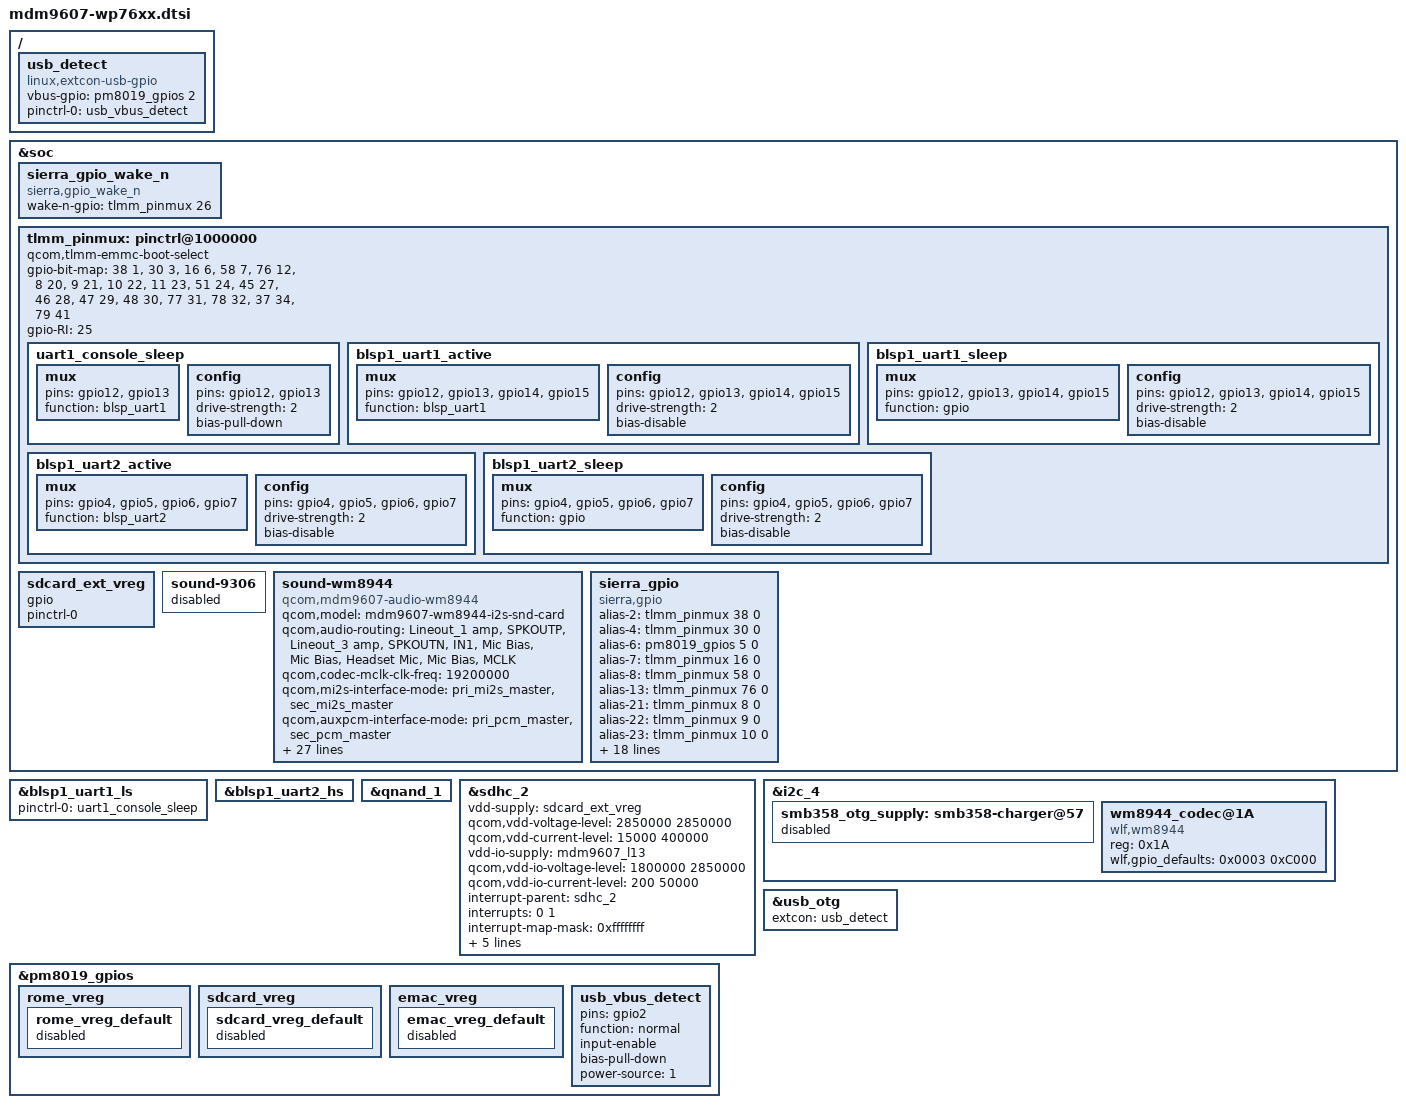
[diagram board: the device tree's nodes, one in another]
/*
 * Copyright (c) 2015-2016, The Linux Foundation. All rights reserved.
 *
 * This program is free software; you can redistribute it and/or modify
 * it under the terms of the GNU General Public License version 2 and
 * only version 2 as published by the Free Software Foundation.
 *
 * This program is distributed in the hope that it will be useful,
 * but WITHOUT ANY WARRANTY; without even the implied warranty of
 * MERCHANTABILITY or FITNESS FOR A PARTICULAR PURPOSE.  See the
 * GNU General Public License for more details.
 */
/*Inherit the shared DTS and overlay the difference */
#include "mdm9607-swi.dtsi"
#include "mdm9607-pinctrl.dtsi"
#include "mdm9607-swimcu.dtsi"

/ {
	usb_detect: usb_detect {
		compatible = "linux,extcon-usb-gpio";
		vbus-gpio = <&pm8019_gpios 2 0>;

		pinctrl-names = "default";
		pinctrl-0 = <&usb_vbus_detect>;
	};
};

&soc {
	sierra_gpio_wake_n {
		compatible = "sierra,gpio_wake_n";
		wake-n-gpio = <&tlmm_pinmux 26 0>;
	};

	tlmm_pinmux: pinctrl@1000000 {
		/*undefine use of qcom,tlmm-emmc-boot-select*/
		qcom,tlmm-emmc-boot-select;

		gpio-bit-map =  <38 1>,
				<30 3>,
				<16 6>,
				<58 7>,
				<76 12>,
				<8 20>,
				<9 21>,
				<10 22>,
				<11 23>,
				<51 24>,
				<45 27>,
				<46 28>,
				<47 29>,
				<48 30>,
				<77 31>,
				<78 32>,
				<37 34>,
				<79 41>;
		gpio-RI = <25>;

		uart1_console_sleep: uart1_console_sleep {
			mux {
				pins = "gpio12", "gpio13";
				function = "blsp_uart1";
			};
			config {
				pins = "gpio12", "gpio13";
				drive-strength = <2>;
				bias-pull-down;
			};
		};

		blsp1_uart1_active: blsp1_uart1_active {
			mux {
				pins = "gpio12", "gpio13", "gpio14", "gpio15";
				function = "blsp_uart1";
			};

			config {
				pins = "gpio12", "gpio13", "gpio14", "gpio15";
				drive-strength = <2>;
				bias-disable;
			};
		};

		blsp1_uart1_sleep: blsp1_uart1_sleep {
			mux {
				pins = "gpio12", "gpio13", "gpio14", "gpio15";
				function = "gpio";
			};

			config {
				pins = "gpio12", "gpio13", "gpio14", "gpio15";
				drive-strength = <2>;
				bias-disable;
			};
		};

		blsp1_uart2_active: blsp1_uart2_active {
			mux {
				pins = "gpio4", "gpio5", "gpio6", "gpio7";
				function = "blsp_uart2";
			};

			config {
				pins = "gpio4", "gpio5", "gpio6", "gpio7";
				drive-strength = <2>;
				bias-disable;
			};
		};

		blsp1_uart2_sleep: blsp1_uart2_sleep {
			mux {
				pins = "gpio4", "gpio5", "gpio6", "gpio7";
				function = "gpio";
			};


			config {
				pins = "gpio4", "gpio5", "gpio6", "gpio7";
				drive-strength = <2>;
				bias-disable;
			};
		};
	};

	sdcard_ext_vreg: sdcard_ext_vreg {
	/* undefine (by overriding) the use of pm-gpio4 *
	 * we don't use pm-gpio4 for sdcard_ext_vreg.   *
	 */
		gpio;
		pinctrl-names;
		pinctrl-0;
	};

	sound-9306 {
		status = "disabled";
	};

	sound-wm8944 {
		compatible = "qcom,mdm9607-audio-wm8944";
		qcom,model = "mdm9607-wm8944-i2s-snd-card";

		qcom,audio-routing =
			"Lineout_1 amp", "SPKOUTP",
			"Lineout_3 amp", "SPKOUTN",
			"IN1", "Mic Bias",
			"Mic Bias", "Headset Mic",
			"Mic Bias", "MCLK";

		qcom,codec-mclk-clk-freq = <19200000>;
		qcom,mi2s-interface-mode = "pri_mi2s_master", "sec_mi2s_master";
		qcom,auxpcm-interface-mode = "pri_pcm_master", "sec_pcm_master";
		asoc-platform = <&pcm0>, <&pcm1>, <&voip>, <&voice>,
				<&loopback>, <&hostless>, <&afe>, <&routing>,
				<&pcm_dtmf>, <&host_pcm>, <&compress>;
		asoc-platform-names = "msm-pcm-dsp.0", "msm-pcm-dsp.1",
				"msm-voip-dsp", "msm-pcm-voice",
				"msm-pcm-loopback", "msm-pcm-hostless",
				"msm-pcm-afe", "msm-pcm-routing",
				"msm-pcm-dtmf", "msm-voice-host-pcm",
				"msm-compress-dsp";
		asoc-cpu = <&dai_pri_auxpcm>, <&dai_sec_auxpcm>,
				<&mi2s_prim>, <&mi2s_sec>, <&dtmf_tx>,
				<&rx_capture_tx>, <&rx_playback_rx>,
				<&tx_capture_tx>, <&tx_playback_rx>,
				<&afe_pcm_rx>, <&afe_pcm_tx>, <&afe_proxy_rx>,
				<&afe_proxy_tx>, <&incall_record_rx>,
				<&incall_record_tx>, <&incall_music_rx>;
		asoc-cpu-names = "msm-dai-q6-auxpcm.1", "msm-dai-q6-auxpcm.2",
				"msm-dai-q6-mi2s.0", "msm-dai-q6-mi2s.1",
				"msm-dai-stub-dev.4", "msm-dai-stub-dev.5",
				"msm-dai-stub-dev.6", "msm-dai-stub-dev.7",
				"msm-dai-stub-dev.8", "msm-dai-q6-dev.224",
				"msm-dai-q6-dev.225", "msm-dai-q6-dev.241",
				"msm-dai-q6-dev.240", "msm-dai-q6-dev.32771",
				"msm-dai-q6-dev.32772", "msm-dai-q6-dev.32773";
		asoc-codec = <&stub_codec>;
		asoc-codec-names = "msm-stub-codec.1";
		/* clk_rf_clk2 should be defined in include/dt-bindings/clock/mdm-clocks-9607.h */
		clocks = <&clock_gcc clk_rf_clk2>;
		clock-names = "wm8944_sysclk";
	};

	sierra_gpio: sierra_gpio {
		compatible = "sierra,gpio";
		alias-2 = <&tlmm_pinmux 38 0>;
		alias-4 = <&tlmm_pinmux 30 0>;
		alias-6 = <&pm8019_gpios 5 0>;
		alias-7 = <&tlmm_pinmux 16 0>;
		alias-8 = <&tlmm_pinmux 58 0>;
		alias-13 = <&tlmm_pinmux 76 0>;
		alias-21 = <&tlmm_pinmux 8 0>;
		alias-22 = <&tlmm_pinmux 9 0>;
		alias-23 = <&tlmm_pinmux 10 0>;
		alias-24 = <&tlmm_pinmux 11 0>;
		alias-25 = <&tlmm_pinmux 51 0>;
		alias-28 = <&tlmm_pinmux 45 0>;
		alias-29 = <&tlmm_pinmux 46 0>;
		alias-30 = <&tlmm_pinmux 47 0>;
		alias-31 = <&tlmm_pinmux 48 0>;
		alias-32 = <&tlmm_pinmux 77 0>;
		alias-33 = <&tlmm_pinmux 78 0>;
		alias-35 = <&tlmm_pinmux 37 0>;
                /* Like SWIMCU pinctrl is not defined inside the device tree,
                 * it requires to know the SWIMCU gpio base address: 200
		 * see: SWIMCU_GPIO_BASE in arch/arm/mach-msm/include/mach/swimcu.h
		 */
		alias-36 = <200 0>;
		alias-37 = <201 0>;
		alias-38 = <202 0>;
		alias-40 = <203 0>;
		alias-41 = <204 0>;
		alias-42 = <&tlmm_pinmux 79 0>;
		alias-RI = <&tlmm_pinmux 25 0>;
		/* WIFI aliases */
		alias-WLAN_EN = <&tlmm_pinmux 58 0>;
		alias-WIFI_IRQ = <&tlmm_pinmux 79 0>;
	};
};

&blsp1_uart1_ls {
	status = "ok";
	pinctrl-names = "default";
	pinctrl-0 = <&uart1_console_sleep>;
};

&blsp1_uart2_hs {
	status = "ok";
};

&qnand_1 {
	status = "ok";
};

&sdhc_2 {
	vdd-supply = <&sdcard_ext_vreg>;
	qcom,vdd-voltage-level = <2850000 2850000>;
	qcom,vdd-current-level = <15000 400000>;

	vdd-io-supply = <&mdm9607_l13>;
	qcom,vdd-io-voltage-level = <1800000 2850000>;
	qcom,vdd-io-current-level = <200 50000>;

	#address-cells = <0>;
	interrupt-parent = <&sdhc_2>;
	interrupts = <0 1>;
	#interrupt-cells = <1>;
	interrupt-map-mask = <0xffffffff>;
	interrupt-map = <0 &intc 0 125 0
			1 &intc 0 221 0>;
	interrupt-names = "hc_irq", "pwr_irq";

	pinctrl-names = "active", "sleep";
	pinctrl-0 = <&sdc2_clk_on &sdc2_cmd_on &sdc2_data_on &sdc2_cd_on>;
	pinctrl-1 = <&sdc2_clk_off &sdc2_cmd_off &sdc2_data_off>;

	status = "ok";
};

&i2c_4 {
	/* SMB358 charger configuration */
	smb358_otg_supply: smb358-charger@57 {
		status = "disabled";
	};
};

&pm8019_gpios {
	/* PMIC GPIO 3 for rome_vreg */
	rome_vreg {
		rome_vreg_default: rome_vreg_default {
			status = "disabled";
		};
	};

	/* sdcard_ext_vreg GPIO 4 */
	sdcard_vreg {
		sdcard_vreg_default: sdcard_vreg_default {
			status = "disabled";
		};
	};

	emac_vreg {
		emac_vreg_default: emac_vreg_default { /* MPP 4 for emac_vreg*/
			status = "disabled";
		};
	};

        usb_vbus_detect: usb_vbus_detect { /* GPIO 2 for VBUS detect */
                        pins = "gpio2";
                        function = "normal";
                        input-enable;
                        bias-pull-down;
                        power-source = <1>;
        };
};

&usb_otg {
	extcon = <&usb_detect>;
	status = "ok";
};

/* Disable the the codec dts */
&i2c_4 {
	wm8944_codec@1A{
		compatible = "wlf,wm8944";
		reg = <0x1A>;
		wlf,gpio_defaults = <0x0003 0xC000>;
	};
};
